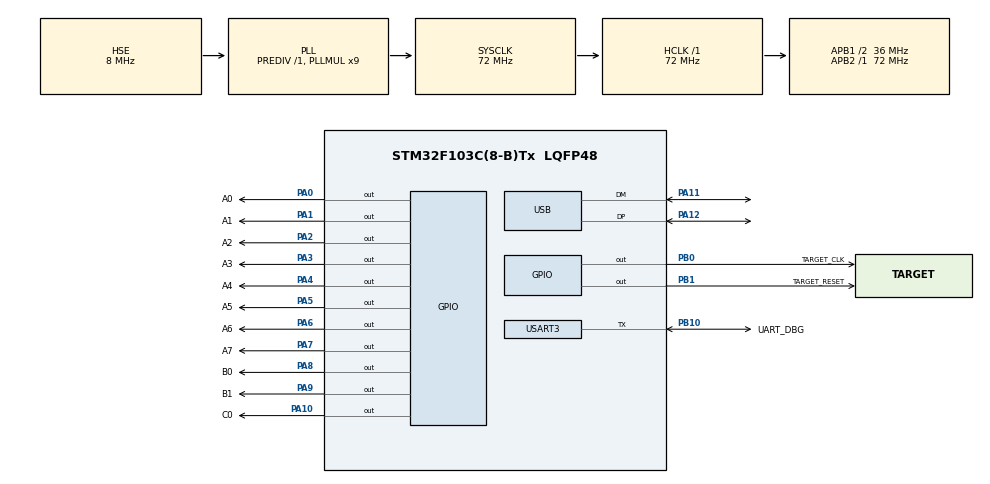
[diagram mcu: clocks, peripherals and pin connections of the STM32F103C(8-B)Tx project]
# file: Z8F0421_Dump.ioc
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Mcu.Family=STM32F1
Mcu.Name=STM32F103C(8-B)Tx
Mcu.Package=LQFP48
NVIC.PriorityGroup=NVIC_PRIORITYGROUP_4
NVIC.USB_LP_CAN1_RX0_IRQn=true\:0\:0\:false\:false\:true\:false\:true\:true
PA0-WKUP.GPIO_Label=A0
PA0-WKUP.Signal=GPIO_Output
PA1.GPIO_Label=A1
PA1.Signal=GPIO_Output
PA10.GPIO_Label=C0
PA10.Signal=GPIO_Output
PA11.Mode=Device
PA11.Signal=USB_DM
PA12.Mode=Device
PA12.Signal=USB_DP
PA13.Mode=Serial_Wire
PA13.Signal=SYS_JTMS-SWDIO
PA14.Mode=Serial_Wire
PA14.Signal=SYS_JTCK-SWCLK
PA2.GPIO_Label=A2
PA2.Signal=GPIO_Output
PA3.GPIO_Label=A3
PA3.Signal=GPIO_Output
PA4.GPIO_Label=A4
PA4.Signal=GPIO_Output
PA5.GPIO_Label=A5
PA5.Signal=GPIO_Output
PA6.GPIO_Label=A6
PA6.Signal=GPIO_Output
PA7.GPIO_Label=A7
PA7.Signal=GPIO_Output
PA8.GPIO_Label=B0
PA8.Signal=GPIO_Output
PA9.GPIO_Label=B1
PA9.Signal=GPIO_Output
PB0.GPIO_Label=TARGET_CLK
PB0.Signal=GPIO_Output
PB1.GPIO_Label=TARGET_RESET
PB1.Signal=GPIO_Output
PB10.GPIO_Label=UART_DBG
PB10.Mode=Half_duplex(single_wire_mode)
PB10.Signal=USART3_TX
PC14-OSC32_IN.Mode=LSE-External-Oscillator
PC14-OSC32_IN.Signal=RCC_OSC32_IN
PC15-OSC32_OUT.Mode=LSE-External-Oscillator
PC15-OSC32_OUT.Signal=RCC_OSC32_OUT
PD0-OSC_IN.Mode=HSE-External-Oscillator
PD0-OSC_IN.Signal=RCC_OSC_IN
PD1-OSC_OUT.Mode=HSE-External-Oscillator
PD1-OSC_OUT.Signal=RCC_OSC_OUT
ProjectManager.HeapSize=0x200
ProjectManager.StackSize=0x400
ProjectManager.TargetToolchain=STM32CubeIDE
RCC.AHBFreq_Value=72000000
RCC.APB1CLKDivider=RCC_HCLK_DIV2
RCC.APB1Freq_Value=36000000
RCC.APB1TimFreq_Value=72000000
RCC.APB2Freq_Value=72000000
RCC.APB2TimFreq_Value=72000000
RCC.HCLKFreq_Value=72000000
RCC.PLLMUL=RCC_PLL_MUL9
RCC.SYSCLKFreq_VALUE=72000000
RCC.SYSCLKSource=RCC_SYSCLKSOURCE_PLLCLK
RCC.USBFreq_Value=48000000
RCC.USBPrescaler=RCC_USBCLKSOURCE_PLL_DIV1_5
USART3.BaudRate=9600
USART3.VirtualMode=VM_ASYNC
USB_DEVICE.CLASS_NAME_FS=CDC
USB_DEVICE.CONFIGURATION_STRING_CDC_FS=Z8 Bypasser
USB_DEVICE.INTERFACE_STRING_CDC_FS=Z8 Dumper Interface
USB_DEVICE.MANUFACTURER_STRING=HouseY2K
USB_DEVICE.PID_CDC_FS=0x0001
USB_DEVICE.PRODUCT_STRING_CDC_FS=HouseY2K Z8 Encore Bypasser
USB_DEVICE.VID=0x1209
USB_DEVICE.VirtualMode=Cdc
USB_DEVICE.VirtualModeFS=Cdc_FS
VP_USB_DEVICE_VS_USB_DEVICE_CDC_FS.Mode=CDC_FS
board=custom

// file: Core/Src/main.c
/* USER CODE BEGIN Header */
/**
  ******************************************************************************
  * @file           : main.c
  * @brief          : Main program body
  ******************************************************************************
  * @attention
  *
  * Copyright (c) 2025 STMicroelectronics.
  * All rights reserved.
  *
  * This software is licensed under terms that can be found in the LICENSE file
  * in the root directory of this software component.
  * If no LICENSE file comes with this software, it is provided AS-IS.
  *
  ******************************************************************************
  */
/* USER CODE END Header */
#include "main.h"
#include "usb_device.h"

UART_HandleTypeDef huart3;

void SystemClock_Config(void);
static void MX_GPIO_Init(void);
static void MX_USART3_UART_Init(void);

int main(void)
{

  /* MCU Configuration--------------------------------------------------------*/

  /* Reset of all peripherals, Initializes the Flash interface and the Systick. */
  HAL_Init();

  /* Configure the system clock */
  SystemClock_Config();

  /* Initialize all configured peripherals */
  MX_GPIO_Init();
  MX_USART3_UART_Init();
  MX_USB_DEVICE_Init();

  /* Infinite loop */
  /* USER CODE BEGIN WHILE */
  fwsetup();
  while (1)
  {
	  fwloop();
    /* USER CODE END WHILE */

  }
}

void SystemClock_Config(void)
{
  RCC_OscInitTypeDef RCC_OscInitStruct = {0};
  RCC_ClkInitTypeDef RCC_ClkInitStruct = {0};
  RCC_PeriphCLKInitTypeDef PeriphClkInit = {0};

  /** Initializes the RCC Oscillators according to the specified parameters
  * in the RCC_OscInitTypeDef structure.
  */
  RCC_OscInitStruct.OscillatorType = RCC_OSCILLATORTYPE_HSE;
  RCC_OscInitStruct.HSEState = RCC_HSE_ON;
  RCC_OscInitStruct.HSEPredivValue = RCC_HSE_PREDIV_DIV1;
  RCC_OscInitStruct.HSIState = RCC_HSI_ON;
  RCC_OscInitStruct.PLL.PLLState = RCC_PLL_ON;
  RCC_OscInitStruct.PLL.PLLSource = RCC_PLLSOURCE_HSE;
  RCC_OscInitStruct.PLL.PLLMUL = RCC_PLL_MUL9;
  if (HAL_RCC_OscConfig(&RCC_OscInitStruct) != HAL_OK)
  {
    Error_Handler();
  }

  /** Initializes the CPU, AHB and APB buses clocks
  */
  RCC_ClkInitStruct.ClockType = RCC_CLOCKTYPE_HCLK|RCC_CLOCKTYPE_SYSCLK
                              |RCC_CLOCKTYPE_PCLK1|RCC_CLOCKTYPE_PCLK2;
  RCC_ClkInitStruct.SYSCLKSource = RCC_SYSCLKSOURCE_PLLCLK;
  RCC_ClkInitStruct.AHBCLKDivider = RCC_SYSCLK_DIV1;
  RCC_ClkInitStruct.APB1CLKDivider = RCC_HCLK_DIV2;
  RCC_ClkInitStruct.APB2CLKDivider = RCC_HCLK_DIV1;

  if (HAL_RCC_ClockConfig(&RCC_ClkInitStruct, FLASH_LATENCY_2) != HAL_OK)
  {
    Error_Handler();
  }
  PeriphClkInit.PeriphClockSelection = RCC_PERIPHCLK_USB;
  PeriphClkInit.UsbClockSelection = RCC_USBCLKSOURCE_PLL_DIV1_5;
  if (HAL_RCCEx_PeriphCLKConfig(&PeriphClkInit) != HAL_OK)
  {
    Error_Handler();
  }
}

static void MX_USART3_UART_Init(void)
{

  huart3.Instance = USART3;
  huart3.Init.BaudRate = 9600;
  huart3.Init.WordLength = UART_WORDLENGTH_8B;
  huart3.Init.StopBits = UART_STOPBITS_1;
  huart3.Init.Parity = UART_PARITY_NONE;
  huart3.Init.Mode = UART_MODE_TX_RX;
  huart3.Init.HwFlowCtl = UART_HWCONTROL_NONE;
  huart3.Init.OverSampling = UART_OVERSAMPLING_16;
  if (HAL_HalfDuplex_Init(&huart3) != HAL_OK)
  {
    Error_Handler();
  }

}

static void MX_GPIO_Init(void)
{
  GPIO_InitTypeDef GPIO_InitStruct = {0};

  /* GPIO Ports Clock Enable */
  __HAL_RCC_GPIOC_CLK_ENABLE();
  __HAL_RCC_GPIOD_CLK_ENABLE();
  __HAL_RCC_GPIOA_CLK_ENABLE();
  __HAL_RCC_GPIOB_CLK_ENABLE();

  /*Configure GPIO pin Output Level */
  HAL_GPIO_WritePin(GPIOA, A0_Pin|A1_Pin|A2_Pin|A3_Pin
                          |A4_Pin|A5_Pin|A6_Pin|A7_Pin
                          |B0_Pin|B1_Pin|C0_Pin, GPIO_PIN_RESET);

  /*Configure GPIO pin Output Level */
  HAL_GPIO_WritePin(GPIOB, TARGET_CLK_Pin|TARGET_RESET_Pin, GPIO_PIN_RESET);

  /*Configure GPIO pins : A0_Pin A1_Pin A2_Pin A3_Pin
                           A4_Pin A5_Pin A6_Pin A7_Pin
                           B0_Pin B1_Pin C0_Pin */
  GPIO_InitStruct.Pin = A0_Pin|A1_Pin|A2_Pin|A3_Pin
                          |A4_Pin|A5_Pin|A6_Pin|A7_Pin
                          |B0_Pin|B1_Pin|C0_Pin;
  GPIO_InitStruct.Mode = GPIO_MODE_OUTPUT_PP;
  GPIO_InitStruct.Pull = GPIO_NOPULL;
  GPIO_InitStruct.Speed = GPIO_SPEED_FREQ_LOW;
  HAL_GPIO_Init(GPIOA, &GPIO_InitStruct);

  /*Configure GPIO pins : TARGET_CLK_Pin TARGET_RESET_Pin */
  GPIO_InitStruct.Pin = TARGET_CLK_Pin|TARGET_RESET_Pin;
  GPIO_InitStruct.Mode = GPIO_MODE_OUTPUT_PP;
  GPIO_InitStruct.Pull = GPIO_NOPULL;
  GPIO_InitStruct.Speed = GPIO_SPEED_FREQ_LOW;
  HAL_GPIO_Init(GPIOB, &GPIO_InitStruct);

}

void Error_Handler(void)
{
  __disable_irq();
  while (1)
  {
  }
}
